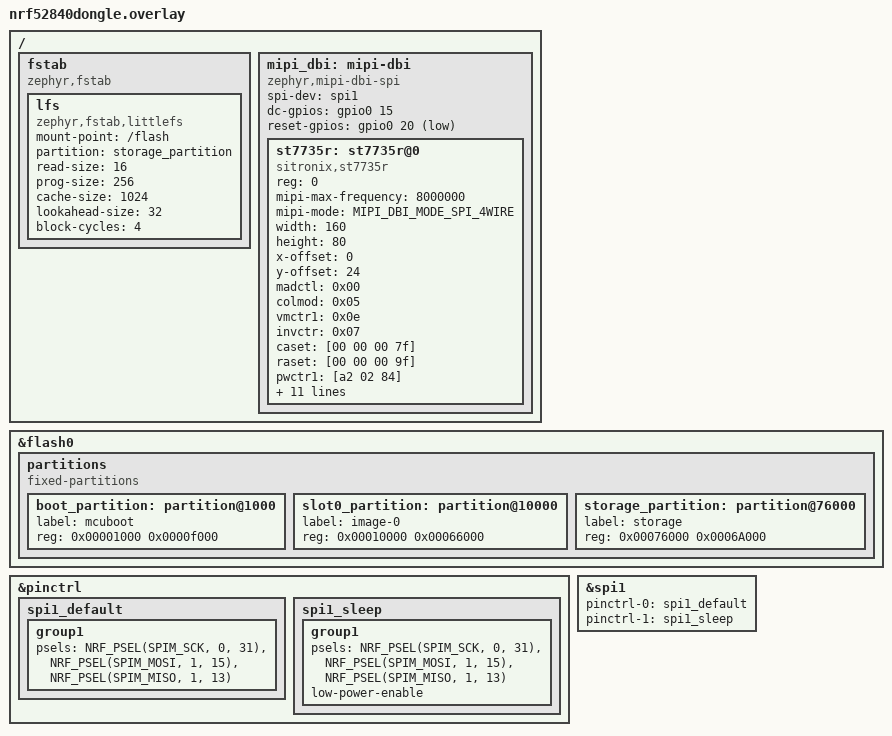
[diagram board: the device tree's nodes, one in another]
/ {
	fstab {
		compatible = "zephyr,fstab";
		lfs: lfs {
			compatible = "zephyr,fstab,littlefs";
			mount-point = "/flash";
			partition = <&storage_partition>;
			read-size=<16>;
			prog-size=<256>;
			cache-size=<1024>;
			lookahead-size=<32>;
			block-cycles=<4>;
		};
	};
};

&flash0 {
  /delete-node/ partitions;
    partitions {
        compatible = "fixed-partitions";
        #address-cells = <1>;
        #size-cells = <1>;
        boot_partition: partition@1000 {
            label = "mcuboot";
            reg = <0x00001000 0x0000f000>;
        };

        slot0_partition: partition@10000 {
            label = "image-0";
            reg = <0x00010000 0x00066000>;
        };
        storage_partition: partition@76000 {
            label = "storage";
            reg = <0x00076000 0x0006A000>;
        };
    };
};

&pinctrl {
    spi1_default: spi1_default {
        group1 {
            psels = <NRF_PSEL(SPIM_SCK,  0, 31)>,
                    <NRF_PSEL(SPIM_MOSI, 1, 15)>,
                    <NRF_PSEL(SPIM_MISO, 1, 13)>;
        };
    };
    spi1_sleep: spi1_sleep {
        group1 {
            psels = <NRF_PSEL(SPIM_SCK,  0, 31)>,
                    <NRF_PSEL(SPIM_MOSI, 1, 15)>,
                    <NRF_PSEL(SPIM_MISO, 1, 13)>;
            low-power-enable;
        };
    };
};

&spi1 {
    status = "okay";
    pinctrl-0 = <&spi1_default>;
    pinctrl-1 = <&spi1_sleep>;
    pinctrl-names = "default", "sleep";
    /* cs-gpios removed — managed manually by TFT library */
};  

/ {
    mipi_dbi: mipi-dbi {
        compatible = "zephyr,mipi-dbi-spi";
        spi-dev = <&spi1>;                            /* phandle to SPI bus */
        dc-gpios    = <&gpio0 15 GPIO_ACTIVE_HIGH>;
        reset-gpios = <&gpio0 20 GPIO_ACTIVE_LOW>;
        #address-cells = <1>;
        #size-cells = <0>;

st7735r: st7735r@0 {
    compatible = "sitronix,st7735r";
    reg = <0>;
    mipi-max-frequency = <8000000>;
    mipi-mode = "MIPI_DBI_MODE_SPI_4WIRE";

    width    = <160>;   /* corrected */
    height   = <80>;    /* corrected */
    x-offset = <0>;
    y-offset = <24>;    /* mini displays often have a 24px offset */

            madctl  = <0x00>;
            colmod  = <0x05>;
            vmctr1  = <0x0e>;
            invctr  = <0x07>;

            caset = [00 00 00 7f];
            raset = [00 00 00 9f];

            pwctr1 = [a2 02 84];
            pwctr2 = [c5];
            pwctr3 = [0a 00];
            pwctr4 = [8a 2a];
            pwctr5 = [8a ee];

            frmctr1 = [01 2c 2d];
            frmctr2 = [01 2c 2d];
            frmctr3 = [01 2c 2d 01 2c 2d];

            gamctrp1 = [10 0e 02 03 0e 07 02 07 0a 12 27 37 00 0d 0e 10];
            gamctrn1 = [10 0e 03 03 0f 06 02 08 0a 13 26 36 00 0d 0e 10];
        };
    };
};

